# GD32F3x0 register map
File version: 1.0
CPU: CM4 r2p1, little endian, no MPU, no FPU, 4 interrupt priority bits
Registers are 32-bit, read-write, reset 0x0 unless marked. A register's access mark holds for its fields unless they carry their own. Offsets are from the block's base; [hi:lo] are bit positions; {n}, {i} and the like mark numbered series.

## SYSCFG — System configuration controller
Base 0x40010000
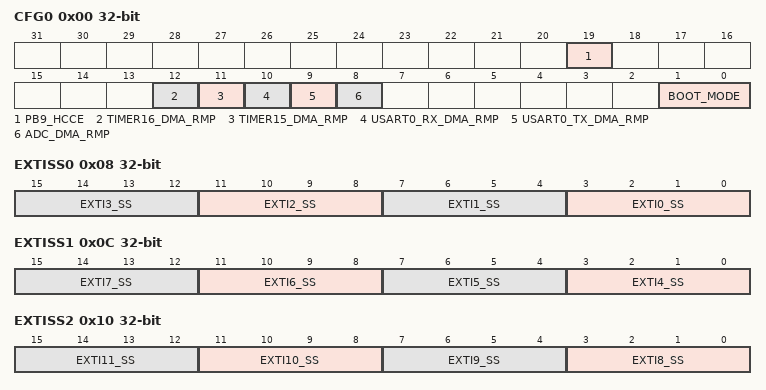
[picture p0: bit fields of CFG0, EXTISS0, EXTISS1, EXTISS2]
0x00 CFG0 — System configuration register 0
  [19] PB9_HCCE — PB9 pin high current capability enable
  [12] TIMER16_DMA_RMP — Timer 16 DMA request remapping enable
  [11] TIMER15_DMA_RMP — Timer 15 DMA request remapping enable
  [10] USART0_RX_DMA_RMP — USART0_RX DMA request remapping enable
  [9] USART0_TX_DMA_RMP — USART0_TX DMA request remapping enable
  [8] ADC_DMA_RMP — ADC DMA request remapping enable
  [1:0] BOOT_MODE ro
0x08 EXTISS0 — EXTI sources selection register 0
  [4n+3:4n] EXTI{n}_SS (n=0..3) — EXTI {n} sources selection
0x0C EXTISS1 — EXTI sources selection register 1
  [4n-13:4n-16] EXTI{n}_SS (n=4..7) — EXTI {n} sources selection
0x10 EXTISS2 — EXTI sources selection register 2
  [4n-29:4n-32] EXTI{n}_SS (n=8..11) — EXTI {n} sources selection
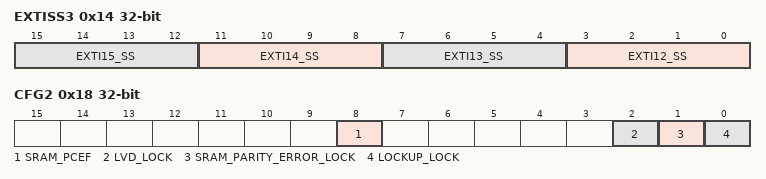
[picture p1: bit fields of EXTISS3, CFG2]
0x14 EXTISS3 — EXTI sources selection register 3
  [4n-45:4n-48] EXTI{n}_SS (n=12..15) — EXTI {n} sources selection
0x18 CFG2 — System configuration register 2
  [8] SRAM_PCEF — SRAM parity check error flag
  [2] LVD_LOCK
  [1] SRAM_PARITY_ERROR_LOCK — SRAM parity check error lock
  [0] LOCKUP_LOCK — Cortex-M4 LOCKUP output lock

## TIMER5 — Basic-timers
Base 0x40001000
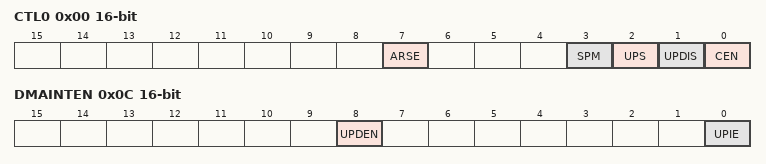
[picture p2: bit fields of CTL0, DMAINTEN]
0x00 CTL0 16-bit — control register 0
  [7] ARSE — Auto-reload preload enable
  [3] SPM — One-pulse mode
  [2] UPS — Update request source
  [1] UPDIS — Update disable
  [0] CEN — Counter enable
0x04 CTL1 16-bit — control register 1
  [6:4] MMC — Master mode selection
0x0C DMAINTEN 16-bit — DMA/Interrupt enable register
  [8] UPDEN — Update DMA request enable
  [0] UPIE — Update interrupt enable
0x10 INTF 16-bit — status register
  [0] UPIF — Update interrupt flag
0x14 SWEVG 16-bit wo — event generation register
  [0] UPG — Update generation
0x24 CNT 16-bit — counter
  [15:0] CNT — Low counter value
0x28 PSC 16-bit — prescaler
  [15:0] PSC — Prescaler value
0x2C CAR 16-bit — auto-reload register
  [15:0] CARL — Low Auto-reload value

## TIMER13 — General-purpose-timers
Base 0x40002000
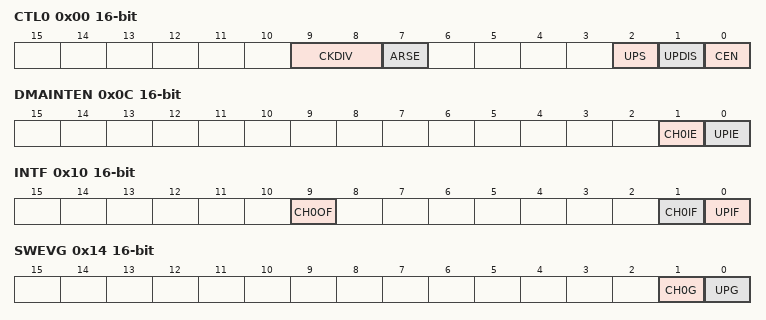
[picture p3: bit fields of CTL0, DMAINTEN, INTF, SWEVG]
0x00 CTL0 16-bit — control register 1
  [9:8] CKDIV — Clock division
  [7] ARSE — Auto-reload preload enable
  [2] UPS — Update request source
  [1] UPDIS — Update disable
  [0] CEN — Counter enable
0x0C DMAINTEN 16-bit — DMA/Interrupt enable register
  [1] CH0IE — Capture/Compare 0 interrupt enable
  [0] UPIE — Update interrupt enable
0x10 INTF 16-bit — interrupt flag register
  [9] CH0OF — Capture/Compare 0 overcapture flag
  [1] CH0IF — Capture/compare 0 interrupt flag
  [0] UPIF — Update interrupt flag
0x14 SWEVG 16-bit wo — event generation register
  [1] CH0G — Capture/compare 0 generation
  [0] UPG — Update generation
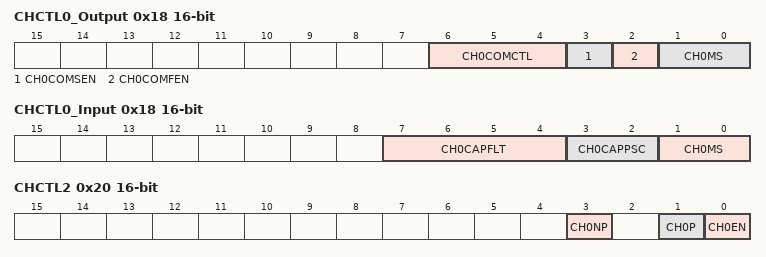
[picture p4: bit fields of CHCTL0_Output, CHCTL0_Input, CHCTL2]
0x18 CHCTL0_Output 16-bit — capture/compare mode register (output mode)
  [6:4] CH0COMCTL — Output Compare 0 mode
  [3] CH0COMSEN — Output Compare 0 preload enable
  [2] CH0COMFEN — Output compare 0 fast enable
  [1:0] CH0MS — Capture/Compare 0 selection
0x18 CHCTL0_Input 16-bit (alternate view of CHCTL0_Output) — capture/compare mode register (input mode)
  [7:4] CH0CAPFLT — Input capture 0 filter
  [3:2] CH0CAPPSC — Input capture 0 prescaler
  [1:0] CH0MS — Capture/Compare 0 selection
0x20 CHCTL2 16-bit — capture/compare enable register
  [3] CH0NP — Capture/Compare 0 output Polarity
  [1] CH0P — Capture/Compare 0 output Polarity
  [0] CH0EN — Capture/Compare 1 output enable
0x24 CNT 16-bit — counter
  [15:0] CNT — counter value
0x28 PSC 16-bit — prescaler
  [15:0] PSC — Prescaler value
0x2C CAR 16-bit — auto-reload register
  [15:0] CARL — Auto-reload value
0x34 CH0CV 16-bit — capture/compare register 0
  [15:0] CH0VAL — Capture/Compare 1 value
0x50 IRMP 16-bit — channel input remap register
  [1:0] CI0_RMP — Timer input 0 remap
0xFC CFG 16-bit — configuration register
  [1] CHVSEL — Write CHxVAL register selection
